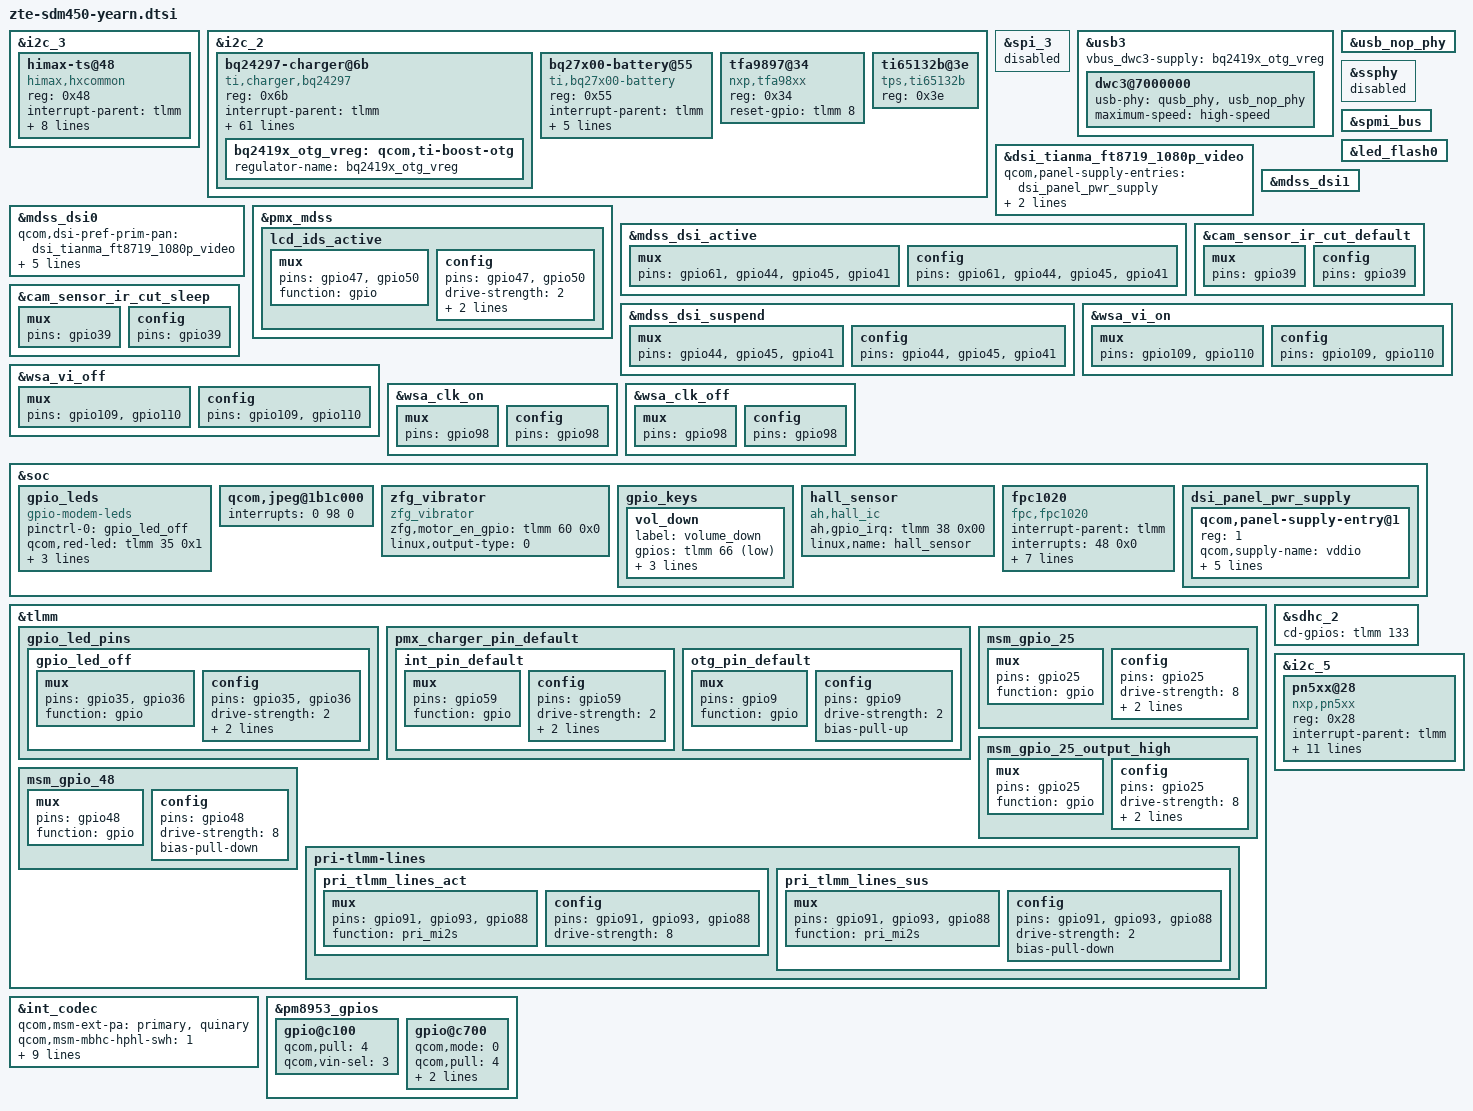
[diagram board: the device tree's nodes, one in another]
/*
 * Copyright (c) 2017, The Linux Foundation. All rights reserved.
 *
 * This program is free software; you can redistribute it and/or modify
 * it under the terms of the GNU General Public License version 2 and
 * only version 2 as published by the Free Software Foundation.
 *
 * This program is distributed in the hope that it will be useful,
 * but WITHOUT ANY WARRANTY; without even the implied warranty of
 * MERCHANTABILITY or FITNESS FOR A PARTICULAR PURPOSE.  See the
 * GNU General Public License for more details.
 */

#include "sdm450-camera-sensor-zfg-blaze.dtsi"

#include "dsi-panel-zfg-tianma-ft8719-6p2-1080p-video.dtsi"

#include "touch-key-backlight-yearn.dtsi"

&i2c_3 { /* BLSP1 QUP3 */
	status = "okay";

	himax-ts@48 {
		compatible = "himax,hxcommon";
		reg = <0x48>;
		interrupt-parent = <&tlmm>;
		interrupts = <65 0x2>;
		vdd-supply = <&pm8953_l17>;
		avdd-supply = <&pm8953_l6>;
		himax,panel-coords = <0 1080 0 2160>;
		himax,display-coords = <0 1080 0 2160>;
		himax,irq-gpio = <&tlmm 65 0x00>;
		himax,rst-gpio = <&tlmm 64 0x00>;
		report_type = <1>;
	};
};

&i2c_2 {
	bq24297-charger@6b {
		compatible = "ti,charger,bq24297";
		reg = <0x6b>;
		interrupt-parent = <&tlmm>;
		interrupts = <59 0x0>;

		pinctrl-names = "default";
		pinctrl-0 = <&int_pin_default &otg_pin_default>;

		ti,irq-gpio = <&tlmm 9 0x00>;

		ti,bq2429x,usb-vlim = <4520>;
		ti,bq2429x,usb-ilim = <500>;
		ti,bq2429x,usb-float-voltage-mv = <4400>;
		ti,bq2429x,usb-ichg = <512>;
		ti,bq2429x,ta-vlim = <4520>;
		ti,bq2429x,ta-ilim = <2000>;
		ti,bq2429x,ta-ichg = <2176>;
		ti,bq2429x,ta-float-voltage-mv = <4400>;
		ti,recharge-mv = <100>;
		ti,bq2429x,software-jeita-supported;
		ti,bq2429x,jeita-hot-degc = <600>;
		ti,bq2429x,jeita-warm-degc = <450>;
		ti,bq2429x,jeita-cool-degc = <100>;
		ti,bq2429x,jeita-cold-degc = <50>;
		ti,bq2429x,jeita-cool-ma = <896>;
		ti,bq2429x,jeita-cool-mv = <4400>;
		ti,bq2429x,jeita-warm-ma = <1024>;
		ti,bq2429x,jeita-warm-mv = <4100>;
		ti,bq2429x,jeita-cold-hysteresis = <20>;
		ti,bq2429x,jeita-hot-hysteresis = <20>;
		ti,bq2429x,thermal-mitigation = <2000 1500 1000 900>;
		ti,bq2429x,precharge-current = <384>;
		ti,bq2429x,termination-current = <128>;
		ti,bq2429x,boost-volt = <4998>;
		ti,bq2429x,boost-current = <1000>;
		ti,bq2429x,enable_term;

		/*--------------------------fot ti bq25601 compatible---------------------------------------*/
		ti,charge_enable-gpio = <&tlmm 3 0x00>;

		ti,bq2560x,usb-vlim = <4520>;
		ti,bq2560x,usb-ilim = <500>;
		ti,bq2560x,usb-vreg = <4400>;
		ti,bq2560x,usb-ichg = <500>;

		ti,bq2560x,ta-vlim = <4520>;
		ti,bq2560x,ta-ilim = <2000>;
		ti,bq2560x,ta-vreg = <4400>;
		ti,bq2560x,ta-ichg = <2000>;

		ti,bq2560x,precharge-current = <384>;
		ti,bq2560x,termination-current = <60>;
		ti,bq2560x,boost-voltage = <4998>;
		ti,bq2560x,boost-current = <1200>;

		ti,bq2560x,stat-pin-ctrl = <0>;
		ti,bq2560x,vac-ovp-threshold = <14300>;

		ti,bq2560x,jeita-hot-degc = <600>;
		ti,bq2560x,jeita-warm-degc = <450>;
		ti,bq2560x,jeita-cool-degc = <100>;
		ti,bq2560x,jeita-cold-degc = <0>;

		ti,bq2560x,jeita-hot-hysteresis = <50>;
		ti,bq2560x,jeita-cold-hysteresis = <50>;

		ti,bq2560x,jeita-cool-ma = <600>;
		ti,bq2560x,jeita-cool-mv = <4352>;
		ti,bq2560x,jeita-warm-ma = <600>;
		ti,bq2560x,jeita-warm-mv = <4100>;

		ti,bq2560x,recharge-mv = <300>;

		ti,bq2560x,enable_term;
		ti,bq2560x,enable_soc_term_charge;
		ti,bq2560x,software-jeita-supported;
		ti,bq2560x,thermal-mitigation = <1500 700 500 500>;

		bq2419x_otg_vreg: qcom,ti-boost-otg {
			regulator-name = "bq2419x_otg_vreg";
		};
	};

	bq27x00-battery@55 {
		compatible = "ti,bq27x00-battery";
		reg = <0x55>;
		interrupt-parent = <&tlmm>;
		interrupts = <139 0x0>;
		qcom,irq-gpio = <&tlmm 139 0x00>;

		/*
		pinctrl-names = "default";
		pinctrl-0 = <&fg_int_active>;
		*/

		qcom,chg-vadc = <&pm8953_vadc>;
		qcom,batt-id-vref-uv = <1800000>;
		qcom,batt-id-rpullup-kohm = <100>;
	};

	
	tfa9897@34 {
		compatible = "nxp,tfa98xx";
		reg = <0x34>;
		reset-gpio = <&tlmm 8 0x0>;
	};
	

	
	ti65132b@3e {
		compatible = "tps,ti65132b";
		reg = <0x3e>;
	};
	
};

&spi_3 {
	status = "disabled";
};

&usb3 {
	vbus_dwc3-supply = <&bq2419x_otg_vreg>;
	dwc3@7000000 {
		usb-phy = <&qusb_phy>, <&usb_nop_phy>;
		maximum-speed = "high-speed";
	};
};

&usb_nop_phy {
	status = "okay";
};

&ssphy {
	status = "disabled";
};

&spmi_bus {
	/delete-node/qcom,pmi8950@2;
	/delete-node/qcom,pmi8950@3;
};

&led_flash0 {
	/delete-property/qcom,flash-source;
	/delete-property/qcom,torch-source;
	/delete-property/qcom,switch-source;
};

&dsi_tianma_ft8719_1080p_video{
	qcom,panel-supply-entries = <&dsi_panel_pwr_supply>;
	qcom,mdss-dsi-panel-timings-phy-v2 = [25 20 08 0A 06 03 04 a0
		25 20 08 0A 06 03 04 a0
		25 20 08 0A 06 03 04 a0
		25 20 08 0A 06 03 04 a0
		25 1D 08 0A 06 03 04 a0];
};
&mdss_dsi0 {
	qcom,dsi-pref-prim-pan = <&dsi_tianma_ft8719_1080p_video>;
	pinctrl-0 = <&mdss_dsi_active &mdss_te_active &lcd_ids_active>;
	qcom,platform-bklight-en-gpio = <&tlmm 41 0>;
	zfg,disp_vsp_en_gpio = <&tlmm 44 0>;
	zfg,disp_vsn_en_gpio = <&tlmm 45 0>;
	/delete-property/lab-supply;
	/delete-property/ibb-supply;
};

&mdss_dsi1 {
	/delete-property/lab-supply;
	/delete-property/ibb-supply;
};

&pmx_mdss {
	lcd_ids_active: lcd_ids_active {
		mux {
			pins = "gpio47","gpio50";
			function = "gpio";
		};
		config {
			pins =  "gpio47","gpio50";
			drive-strength = <2>;
			bias-pull-down;
			input-enable;
		};
	};
};
&mdss_dsi_active {
	mux {
		pins = "gpio61", "gpio44","gpio45", "gpio41";
	};

	config {
		pins = "gpio61", "gpio44","gpio45", "gpio41";
	};
};

&mdss_dsi_suspend {
	mux {
		pins = "gpio44","gpio45", "gpio41";
	};

	config {
		pins = "gpio44","gpio45", "gpio41";
	};
};


&cam_sensor_ir_cut_default {
	/* RESET, STANDBY */
	mux {
		pins = "gpio39";
	};

	config {
		pins = "gpio39";
	};
};

&cam_sensor_ir_cut_sleep {
	/* RESET, STANDBY */
	mux {
		pins = "gpio39";
	};

	config {
		pins = "gpio39";
	};
};
/*end*/

&wsa_vi_on {
	mux {
		pins = "gpio109", "gpio110";
	};

	config {
		pins = "gpio109", "gpio110";
	};
};

&wsa_vi_off {
	mux {
		pins = "gpio109", "gpio110";
	};

	config {
		pins = "gpio109", "gpio110";
	};
};
&wsa_clk_on {
	mux {
		pins = "gpio98";
	};

	config {
		pins = "gpio98";
	};
};

&wsa_clk_off {
	mux {
		pins = "gpio98";
	};

	config {
		pins = "gpio98";
	};
};
/*end*/

&soc {
	
	gpio_leds {
		compatible = "gpio-modem-leds";
		status = "okay";
		pinctrl-names = "default";
		pinctrl-0 = <&gpio_led_off>;
		qcom,red-led = <&tlmm 35 0x1>;
		qcom,green-led = <&tlmm 36 0x1>;
		/*qcom,trickle_red-led = <&tlmm 3 0x1>;*/
		qcom,blink-on-time = <500>;
		qcom,blink-off-time = <1500>;
	};

	
	qcom,jpeg@1b1c000 {
		interrupts = <0 98 0>;
	};

	zfg_vibrator {
		compatible = "zfg_vibrator";
		zfg,motor_en_gpio = <&tlmm 60 0x0>;
		linux,output-type = <0>;
	};

	gpio_keys {
		vol_down {
			label = "volume_down";
			gpios = <&tlmm 66 0x1>;
			linux,input-type = <1>;
			linux,code = <114>;
			debounce-interval = <15>;
		};
	};


	hall_sensor {
		compatible = "ah,hall_ic";
		ah,gpio_irq = <&tlmm 38 0x00>;
		linux,name = "hall_sensor";
	};
/*end*/
/*Added by chenhui for fpc1023, begin*/
	fpc1020 {
		status = "ok";
		compatible = "fpc,fpc1020";
		interrupt-parent = <&tlmm>;
		interrupts = <48 0x0>;
		fpc,gpio_rst	= <&tlmm 25 0x0>;
		fpc,gpio_irq	= <&tlmm 48 0x0>;
		fpc,gpio_pwr	= <&tlmm 94 0x0>;
		fpc,enable-on-boot;
		/* fpc,enable-wakeup; */

		pinctrl-names = "fpc1020_reset_reset",
		"fpc1020_reset_active",
		"fpc1020_irq_active";

		pinctrl-0 = <&msm_gpio_25>;
		pinctrl-1 = <&msm_gpio_25_output_high>;
		pinctrl-2 = <&msm_gpio_48>;
	};
/*Added by chenhui for fpc1023, end*/

	dsi_panel_pwr_supply: dsi_panel_pwr_supply {
		qcom,panel-supply-entry@1 {
			reg = <1>;
			qcom,supply-name = "vddio";
			qcom,supply-min-voltage = <1800000>;
			qcom,supply-max-voltage = <1800000>;
			qcom,supply-enable-load = <100000>;
			qcom,supply-disable-load = <100>;
			qcom,supply-post-on-sleep = <1>;
		};
	};
};

&tlmm {
	gpio_led_pins {
		gpio_led_off: gpio_led_off {
			mux {
				pins = "gpio35", "gpio36";
				function = "gpio";
			};

			config {
				pins = "gpio35", "gpio36";
				drive-strength = <2>;
				bias-disable;
				output-low;
			};
		};
	};
	pmx_charger_pin_default {
		int_pin_default: int_pin_default {
			mux {
				pins = "gpio59";
				function = "gpio";
			};

			config {
				pins = "gpio59";
				drive-strength = <2>;
				bias-pull-up;
				input-enable;
			};
		};
		otg_pin_default: otg_pin_default {
			mux {
				pins = "gpio9";
				function = "gpio";
			};

			config {
				pins = "gpio9";
				drive-strength = <2>;
				bias-pull-up;
			};
		};
	};

	msm_gpio_25: msm_gpio_25{
		mux {
			pins = "gpio25";
			function = "gpio";
		};

		config {
			pins = "gpio25";
			drive-strength = <8>;
			bias-disable;
			output-low;
		};
	};
	msm_gpio_25_output_high: msm_gpio_25_output_high {
		mux {
			pins = "gpio25";
			function = "gpio";
		};

		config {
			pins = "gpio25";
			drive-strength = <8>;
			bias-disable;
			output-high;
		};
	};

	msm_gpio_48: msm_gpio_48 {
		mux {
			pins = "gpio48";
			function = "gpio";
		};

		config {
			pins = "gpio48";
			drive-strength = <8>;
			bias-pull-down;
		};
	};

	pri-tlmm-lines {
			pri_tlmm_lines_act: pri_tlmm_lines_act {
				mux {
					pins = "gpio91", "gpio93", "gpio88";
					function = "pri_mi2s";
				};

				config {
					pins = "gpio91", "gpio93", "gpio88";
					drive-strength = <8>;
				};
			};

			pri_tlmm_lines_sus: pri_tlmm_lines_sus {
				mux {
					pins = "gpio91", "gpio93", "gpio88";
					function = "pri_mi2s";
				};

				config {
					pins = "gpio91", "gpio93", "gpio88";
					drive-strength = <2>;
					bias-pull-down;
				};
			};
		};
};

&int_codec {
	qcom,msm-ext-pa = "primary","quinary";
	qcom,msm-mbhc-hphl-swh = <1>;
	qcom,msm-mbhc-gnd-swh = <1>;
	qcom,msm-hs-micbias-type = "internal";
	qcom,audio-routing =
		"RX_BIAS", "MCLK",
		"SPK_RX_BIAS", "MCLK",
		"INT_LDO_H", "MCLK",
		"MIC BIAS External", "Handset Mic",
		"MIC BIAS Internal2", "Headset Mic",
		"MIC BIAS External", "Secondary Mic",
		"AMIC1", "MIC BIAS External",
		"AMIC2", "MIC BIAS Internal2",
		"AMIC3", "MIC BIAS External";
		/* WSA_SPK OUT", "VDD_WSA_SWITCH", */
		/* "SpkrMono WSA_IN", "WSA_SPK OUT"; */

	/delete-property/ asoc-wsa-codec-names;
	/delete-property/ asoc-wsa-codec-prefixes;

	/delete-property/ msm-vdd-wsa-switch-supply;
	/delete-property/ qcom,msm-vdd-wsa-switch-voltage;
	/delete-property/ qcom,msm-vdd-wsa-switch-current;
	/delete-property/ qcom,hdmi-dba-codec-rx;
};


&sdhc_2 {
	cd-gpios = <&tlmm 133 0x0>;
};


&i2c_5 {
	/delete-node/nq@28;
};

&i2c_5 {
	pn5xx@28{
		compatible = "nxp,pn5xx";
		reg = <0x28>;
		interrupt-parent = <&tlmm>;
		interrupts = <17 0>;
		nxp,pn5xx-irq = <&tlmm 17 0x00>;
		nxp,pn5xx-ven = <&tlmm 16 0x00>;
		nxp,pn5xx-fw-dwnld = <&tlmm 62 0x00>;
		nxp,pn5xx-ese-pwr = <&tlmm 141 0x00>;
		//nxp,pn5xx-swp2-pwr = <&tlmm129 0x00>;
		//nxp,int_active_low = <0>;
		nxp,pn5xx-clkreq = <&pm8953_gpios 2 0x00>;
		nxp,clk-src = "BBCLK2";
		interrupt-names = "nfc_irq";
		pinctrl-names = "nfc_active","nfc_suspend";
		pinctrl-0 = <&nfc_int_active &nfc_disable_active>;
		pinctrl-1 = <&nfc_int_suspend &nfc_disable_suspend>;
		clocks = <&clock_gcc clk_bb_clk2_pin>;
		clock-names = "bb_clk2";
	};
};
&pm8953_gpios {
	/* GPIO 2 (NFC_CLK_REQ) */
	gpio@c100 {
		qcom,pull = <4>;
		qcom,vin-sel = <3>;
	};

	/* GPIO 8 (typeC is not supported) */
	gpio@c700 {
		qcom,mode = <0>;
		qcom,pull = <4>;
		qcom,vin-sel = <2>;
		qcom,src-sel = <0>;
		status = "okay";
	};
};
